# ipro7 register map
Vendor: intelpro; Series: BTBLE
CPU: ipro7, little endian
Registers are 32-bit, read-write, reset 0x0 unless marked. A register's access mark holds for its fields unless they carry their own. Offsets are from the block's base; [hi:lo] are bit positions.

## SPI0
Base 0x3000D000
Same registers: SPI1 0x3001E000
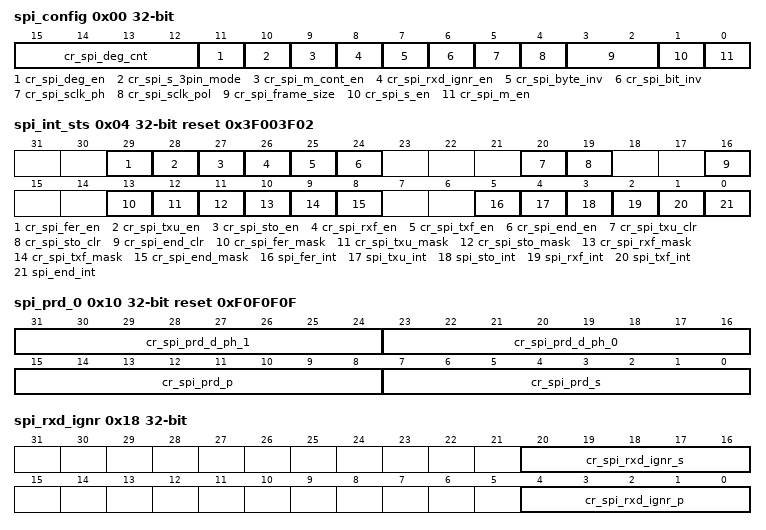
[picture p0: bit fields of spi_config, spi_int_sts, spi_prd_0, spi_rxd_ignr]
0x00 spi_config
  [15:12] cr_spi_deg_cnt — De-glitch function cycle count
  [11] cr_spi_deg_en — Enable signal of all input de-glitch function
  [10] cr_spi_s_3pin_mode — SPI slave 3-pin mode 1'b0: 4-pin mode (SS_n is enabled) 1'b1: 3-pin mode (SS_n is disabled / don't care)
  [9] cr_spi_m_cont_en — Enable signal of master continuous transfer mode 1'b0: Disabled, SS_n will de-assert between each data frame 1'b1: Enabled, SS_n will stay asserted between each consecutive data frame if the next data is valid in the FIFO
  [8] cr_spi_rxd_ignr_en — Enable signal of RX data ignore function
  [7] cr_spi_byte_inv — Byte-inverse signal for each FIFO entry data 0: Byte[0] is sent out first 1: Byte[3] is sent out first
  [6] cr_spi_bit_inv — Bit-inverse signal for each data byte 0: Each byte is sent out MSB-first 1: Each byte is sent out LSB-first
  [5] cr_spi_sclk_ph — SCLK clock phase inverse signal
  [4] cr_spi_sclk_pol — SCLK polarity 0: SCLK output LOW at IDLE state 1: SCLK output HIGH at IDLE state
  [3:2] cr_spi_frame_size — SPI frame size (also the valid width for each FIFO entry) 2'd0: 8-bit 2'd1: 16-bit 2'd2: 24-bit 2'd3: 32-bit
  [1] cr_spi_s_en — Enable signal of SPI Slave function, Master and Slave should not be both enabled at the same time (This bit becomes don't-care if cr_spi_m_en is enabled)
  [0] cr_spi_m_en — Enable signal of SPI Master function Asserting this bit will trigger the transaction, and should be de-asserted after finish
0x04 spi_int_sts reset 0x3F003F02 (reset mask 0xFFFFFFC0)
  [29] cr_spi_fer_en — Interrupt enable of spi_fer_int
  [28] cr_spi_txu_en — Interrupt enable of spi_txu_int
  [27] cr_spi_sto_en — Interrupt enable of spi_sto_int
  [26] cr_spi_rxf_en — Interrupt enable of spi_rxv_int
  [25] cr_spi_txf_en — Interrupt enable of spi_txe_int
  [24] cr_spi_end_en — Interrupt enable of spi_end_int
  [20] cr_spi_txu_clr — Interrupt clear of spi_txu_int
  [19] cr_spi_sto_clr — Interrupt clear of spi_sto_int
  [16] cr_spi_end_clr — Interrupt clear of spi_end_int
  [13] cr_spi_fer_mask — Interrupt mask of spi_fer_int
  [12] cr_spi_txu_mask — Interrupt mask of spi_txu_int
  [11] cr_spi_sto_mask — Interrupt mask of spi_sto_int
  [10] cr_spi_rxf_mask — Interrupt mask of spi_rxv_int
  [9] cr_spi_txf_mask — Interrupt mask of spi_txe_int
  [8] cr_spi_end_mask — Interrupt mask of spi_end_int
  [5] spi_fer_int ro — SPI TX/RX FIFO error interrupt, auto-cleared when FIFO overflow/underflow error flag is cleared
  [4] spi_txu_int ro — SPI slave mode TX underrun error flag, triggered when TXD is not ready during transfer in slave mode
  [3] spi_sto_int ro — SPI slave mode transfer time-out interrupt, triggered when SPI bus is idle for a given value
  [2] spi_rxf_int ro — SPI RX FIFO ready (rx_fifo_cnt > rx_fifo_th) interrupt, auto-cleared when data is popped
  [1] spi_txf_int ro — SPI TX FIFO ready (tx_fifo_cnt > tx_fifo_th) interrupt, auto-cleared when data is pushed
  [0] spi_end_int ro — SPI transfer end interrupt, shared by both master and slave mode Master mode: Triggered when the final frame is transferred Slave mode: Triggered when CS_n is de-asserted
0x08 spi_bus_busy (reset mask 0xFFFFFFFE)
  [0] sts_spi_bus_busy ro — Indicator of SPI bus busy
0x10 spi_prd_0 reset 0xF0F0F0F
  [31:24] cr_spi_prd_d_ph_1 — Length of DATA phase 1 (please refer to "Timing" tab)
  [23:16] cr_spi_prd_d_ph_0 — Length of DATA phase 0 (please refer to "Timing" tab)
  [15:8] cr_spi_prd_p — Length of STOP condition (please refer to "Timing" tab)
  [7:0] cr_spi_prd_s — Length of START condition (please refer to "Timing" tab)
0x14 spi_prd_1 reset 0xF
  [7:0] cr_spi_prd_i — Length of INTERVAL between frame (please refer to "Timing" tab)
0x18 spi_rxd_ignr
  [20:16] cr_spi_rxd_ignr_s — Starting point of RX data ignore function
  [4:0] cr_spi_rxd_ignr_p — Stopping point of RX data ignore function
0x1C spi_sto_value reset 0xFFF
  [11:0] cr_spi_sto_value — Time-out value for spi_sto_int triggering
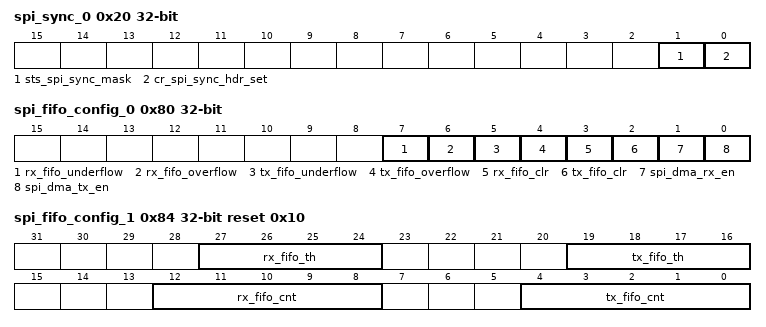
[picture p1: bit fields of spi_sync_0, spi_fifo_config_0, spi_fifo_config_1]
0x20 spi_sync_0 (reset mask 0xFFFFFFFD)
  [1] sts_spi_sync_mask ro — Indicator of SPI sync header function mask is active
  [0] cr_spi_sync_hdr_set — Set SPI sync header function. Note: This function only supports 4-byte header, using 8-bit frame mode
0x24 spi_sync_1
  [31:0] cr_spi_sync_hdr — SPI sync header
0x80 spi_fifo_config_0 (reset mask 0xFFFFFF0F)
  [7] rx_fifo_underflow ro — Underflow flag of RX FIFO, can be cleared by rx_fifo_clr
  [6] rx_fifo_overflow ro — Overflow flag of RX FIFO, can be cleared by rx_fifo_clr
  [5] tx_fifo_underflow ro — Underflow flag of TX FIFO, can be cleared by tx_fifo_clr
  [4] tx_fifo_overflow ro — Overflow flag of TX FIFO, can be cleared by tx_fifo_clr
  [3] rx_fifo_clr — Clear signal of RX FIFO
  [2] tx_fifo_clr — Clear signal of TX FIFO
  [1] spi_dma_rx_en — Enable signal of dma_rx_req/ack interface
  [0] spi_dma_tx_en — Enable signal of dma_tx_req/ack interface
0x84 spi_fifo_config_1 reset 0x10 (reset mask 0xFFFFE0E0)
  [27:24] rx_fifo_th — RX FIFO threshold, dma_rx_req will not be asserted if rx_fifo_cnt is less than this value
  [19:16] tx_fifo_th — TX FIFO threshold, dma_tx_req will not be asserted if tx_fifo_cnt is less than this value
  [12:8] rx_fifo_cnt ro — RX FIFO available count (unit: byte)
  [4:0] tx_fifo_cnt ro — TX FIFO available count (unit: byte)
0x88 spi_fifo_wdata
  [31:0] spi_fifo_wdata wo — TX FIFO write data port Note: Partial valid if cr_spi_frame_size is set to different value: 2'd0 (8-bit frame): Only [7:0] are valid and [31:8] are don't-care 2'd1 (16-bit frame): Only [15:0] are valid and [31:16] are don't-care 2'd2 (24-bit frame): Only [23:0] are valid and [31:24] are don't-care 2'd3 (32-bit frame): Entire [31:0] are valid
0x8C spi_fifo_rdata reset not defined
  [31:0] spi_fifo_rdata ro — RX FIFO read data port Note: Partial valid if cr_spi_frame_size is set to different value: 2'd0 (8-bit frame): Only [7:0] are valid and [31:8] are all 0s 2'd1 (16-bit frame): Only [15:0] are valid and [31:16] are all 0s 2'd2 (24-bit frame): Only [23:0] are valid and [31:24] are all 0s 2'd3 (32-bit frame): Entire [31:0] is valid
0xFC backup_io_en
  [0] backup_io_en
